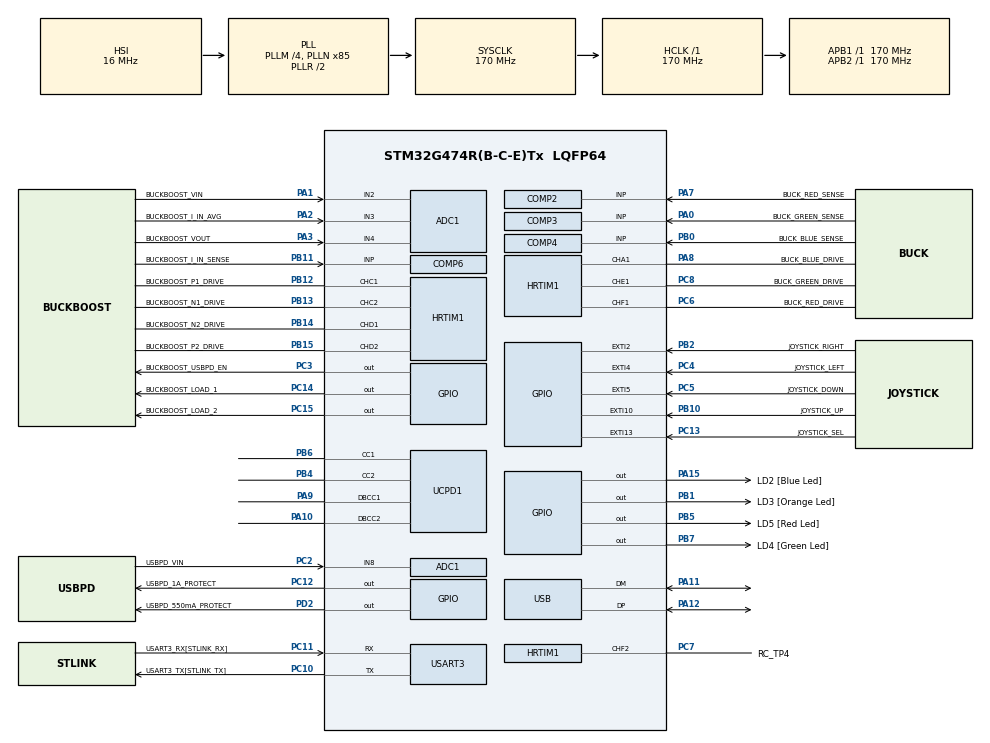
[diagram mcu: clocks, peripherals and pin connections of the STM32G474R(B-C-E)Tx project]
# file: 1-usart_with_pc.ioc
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ADC1.Channel-0\#ChannelRegularConversion=ADC_CHANNEL_8
ADC1.NbrOfConversionFlag=1
ADC1.OffsetNumber-0\#ChannelRegularConversion=ADC_OFFSET_NONE
ADC1.Rank-0\#ChannelRegularConversion=1
ADC1.SamplingTime-0\#ChannelRegularConversion=ADC_SAMPLETIME_2CYCLES_5
ADC1.master=1
DAC3.DAC_Channel-DAC_OUT2_Int=DAC_CHANNEL_2
Mcu.Family=STM32G4
Mcu.Name=STM32G474R(B-C-E)Tx
Mcu.Package=LQFP64
NVIC.ADC1_2_IRQn=true\:0\:0\:false\:false\:true\:true\:true
NVIC.EXTI15_10_IRQn=true\:0\:0\:false\:false\:true\:true\:true
NVIC.EXTI2_IRQn=true\:0\:0\:false\:false\:true\:true\:true
NVIC.EXTI4_IRQn=true\:0\:0\:false\:false\:true\:true\:true
NVIC.EXTI9_5_IRQn=true\:0\:0\:false\:false\:true\:true\:true
NVIC.HRTIM1_Master_IRQn=true\:0\:0\:false\:false\:true\:true\:true
NVIC.HRTIM1_TIMF_IRQn=true\:0\:0\:false\:false\:true\:true\:true
NVIC.PriorityGroup=NVIC_PRIORITYGROUP_4
NVIC.USART3_IRQn=true\:0\:0\:false\:false\:true\:true\:true
NVIC.USB_HP_IRQn=true\:0\:0\:false\:false\:true\:true\:true
PA0.GPIO_Label=BUCK_GREEN_SENSE
PA0.Mode=INP
PA0.Signal=COMP3_INP
PA1.GPIO_Label=BUCKBOOST_VIN
PA1.Mode=IN2-Single-Ended
PA1.Signal=ADC1_IN2
PA10.Mode=EnableDeadBattery
PA10.Signal=UCPD1_DBCC2
PA11.Mode=Device
PA11.Signal=USB_DM
PA12.Mode=Device
PA12.Signal=USB_DP
PA13.Mode=Serial_Wire
PA13.Signal=SYS_JTMS-SWDIO
PA14.Mode=Serial_Wire
PA14.Signal=SYS_JTCK-SWCLK
PA15.GPIO_Label=LD2 [Blue Led]
PA15.Signal=GPIO_Output
PA2.GPIO_Label=BUCKBOOST_I_IN_AVG
PA2.Mode=IN3-Single-Ended
PA2.Signal=ADC1_IN3
PA3.GPIO_Label=BUCKBOOST_VOUT
PA3.Mode=IN4-Single-Ended
PA3.Signal=ADC1_IN4
PA7.GPIO_Label=BUCK_RED_SENSE
PA7.Mode=INP
PA7.Signal=COMP2_INP
PA8.GPIO_Label=BUCK_BLUE_DRIVE
PA8.Mode=Output_TA1
PA8.Signal=HRTIM1_CHA1
PA9.Mode=EnableDeadBattery
PA9.Signal=UCPD1_DBCC1
PB0.GPIO_Label=BUCK_BLUE_SENSE
PB0.Mode=INP
PB0.Signal=COMP4_INP
PB1.GPIO_Label=LD3 [Orange Led]
PB1.Signal=GPIO_Output
PB10.GPIO_Label=JOYSTICK_UP
PB10.GPIO_PuPd=GPIO_PULLUP
PB10.Signal=GPXTI10
PB11.GPIO_Label=BUCKBOOST_I_IN_SENSE
PB11.Mode=INP
PB11.Signal=COMP6_INP
PB12.GPIO_Label=BUCKBOOST_P1_DRIVE
PB12.Mode=Output_TC1TC2
PB12.Signal=HRTIM1_CHC1
PB13.GPIO_Label=BUCKBOOST_N1_DRIVE
PB13.Mode=Output_TC1TC2
PB13.Signal=HRTIM1_CHC2
PB14.GPIO_Label=BUCKBOOST_N2_DRIVE
PB14.Mode=Output_TD1TD2
PB14.Signal=HRTIM1_CHD1
PB15.GPIO_Label=BUCKBOOST_P2_DRIVE
PB15.Mode=Output_TD1TD2
PB15.Signal=HRTIM1_CHD2
PB2.GPIO_Label=JOYSTICK_RIGHT
PB2.GPIO_PuPd=GPIO_PULLUP
PB2.Signal=GPXTI2
PB3.Signal=SYS_JTDO-SWO
PB4.Mode=Sink_AllSignals
PB4.Signal=UCPD1_CC2
PB5.GPIO_Label=LD5 [Red Led]
PB5.Signal=GPIO_Output
PB6.Mode=Sink_AllSignals
PB6.Signal=UCPD1_CC1
PB7.GPIO_Label=LD4 [Green Led]
PB7.Signal=GPIO_Output
PC10.GPIO_Label=USART3_TX[STLINK_TX]
PC10.GPIO_Speed=GPIO_SPEED_FREQ_MEDIUM
PC10.Mode=Asynchronous
PC10.Signal=USART3_TX
PC11.GPIO_Label=USART3_RX[STLINK_RX]
PC11.GPIO_Speed=GPIO_SPEED_FREQ_MEDIUM
PC11.Mode=Asynchronous
PC11.Signal=USART3_RX
PC12.GPIO_Label=USBPD_1A_PROTECT
PC12.Signal=GPIO_Output
PC13.GPIO_Label=JOYSTICK_SEL
PC13.GPIO_PuPd=GPIO_PULLUP
PC13.Signal=GPXTI13
PC14-OSC32_IN.GPIO_Label=BUCKBOOST_LOAD_1
PC14-OSC32_IN.Signal=GPIO_Output
PC15-OSC32_OUT.GPIO_Label=BUCKBOOST_LOAD_2
PC15-OSC32_OUT.Signal=GPIO_Output
PC2.GPIO_Label=USBPD_VIN
PC2.Mode=IN8-Single-Ended
PC2.Signal=ADC1_IN8
PC3.GPIO_Label=BUCKBOOST_USBPD_EN
PC3.Signal=GPIO_Output
PC4.GPIO_Label=JOYSTICK_LEFT
PC4.GPIO_PuPd=GPIO_PULLUP
PC4.Signal=GPXTI4
PC5.GPIO_Label=JOYSTICK_DOWN
PC5.GPIO_PuPd=GPIO_PULLUP
PC5.Signal=GPXTI5
PC6.GPIO_Label=BUCK_RED_DRIVE
PC6.Mode=Output_TF1TF2
PC6.Signal=HRTIM1_CHF1
PC7.GPIO_Label=RC_TP4
PC7.Mode=Output_TF1TF2
PC7.Signal=HRTIM1_CHF2
PC8.GPIO_Label=BUCK_GREEN_DRIVE
PC8.Mode=Output_TE1
PC8.Signal=HRTIM1_CHE1
PD2.GPIO_Label=USBPD_550mA_PROTECT
PD2.Signal=GPIO_Output
ProjectManager.HeapSize=0x200
ProjectManager.StackSize=0x400
ProjectManager.TargetToolchain=STM32CubeIDE
RCC.ADC12Freq_Value=170000000
RCC.ADC345Freq_Value=170000000
RCC.AHBFreq_Value=170000000
RCC.APB1Freq_Value=170000000
RCC.APB1TimFreq_Value=170000000
RCC.APB2Freq_Value=170000000
RCC.APB2TimFreq_Value=170000000
RCC.CK48CLockSelection=RCC_USBCLKSOURCE_HSI48
RCC.CortexFreq_Value=170000000
RCC.EXTERNAL_CLOCK_VALUE=12288000
RCC.HCLKFreq_Value=170000000
RCC.HSE_VALUE=8000000
RCC.HSI48_VALUE=48000000
RCC.HSI_VALUE=16000000
RCC.LSE_VALUE=32768
RCC.PLLM=RCC_PLLM_DIV4
RCC.PLLN=85
RCC.PLLP=RCC_PLLP_DIV8
RCC.PLLQ=RCC_PLLQ_DIV8
RCC.SYSCLKFreq_VALUE=170000000
RCC.SYSCLKSource=RCC_SYSCLKSOURCE_PLLCLK
RCC.USBFreq_Value=48000000
RCC.VCOOutputFreq_Value=340000000
USART3.ClockPrescaler=PRESCALER_DIV4
USART3.VirtualMode-Asynchronous=VM_ASYNC
USART3.WordLength=WORDLENGTH_8B
VP_COMP2_VS_DAC3OUT2.Mode=INM_DAC3OUT2
VP_COMP3_VS_DAC3OUT1.Mode=INM_DAC3OUT1
VP_COMP4_VS_DAC1OUT1.Mode=INM_DAC1OUT1
VP_COMP6_VS_DAC2OUT1.Mode=INM_DAC2OUT1
VP_DAC1_VS_DACI1.Mode=DAC_OUT1_Int
VP_DAC2_VS_DACI1.Mode=DAC_OUT1_Int
VP_DAC3_VS_DACI1.Mode=DAC_OUT1_Int
VP_DAC3_VS_DACI2.Mode=DAC_OUT2_Int
VP_SYS_VS_DBSignals.Mode=DisableDeadBatterySignals
board=B-G474E-DPOW1

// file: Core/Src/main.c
/* USER CODE BEGIN Header */
/**
  ******************************************************************************
  * @file           : main.c
  * @brief          : Main program body
  ******************************************************************************
  * @attention
  *
  * <h2><center>&copy; Copyright (c) 2020 STMicroelectronics.
  * All rights reserved.</center></h2>
  *
  * This software component is licensed by ST under BSD 3-Clause license,
  * the "License"; You may not use this file except in compliance with the
  * License. You may obtain a copy of the License at:
  *                        opensource.org/licenses/BSD-3-Clause
  *
  ******************************************************************************
  */
/* USER CODE END Header */

#include "main.h"

/* USER CODE BEGIN PD */
#define LF 0x0A
/* USER CODE END PD */

ADC_HandleTypeDef hadc1;

COMP_HandleTypeDef hcomp2;
COMP_HandleTypeDef hcomp3;
COMP_HandleTypeDef hcomp4;
COMP_HandleTypeDef hcomp6;

DAC_HandleTypeDef hdac1;
DAC_HandleTypeDef hdac2;
DAC_HandleTypeDef hdac3;

HRTIM_HandleTypeDef hhrtim1;

UART_HandleTypeDef huart3;

PCD_HandleTypeDef hpcd_USB_FS;

void SystemClock_Config(void);
static void MX_GPIO_Init(void);
static void MX_ADC1_Init(void);
static void MX_COMP2_Init(void);
static void MX_COMP3_Init(void);
static void MX_COMP4_Init(void);
static void MX_COMP6_Init(void);
static void MX_DAC1_Init(void);
static void MX_DAC2_Init(void);
static void MX_DAC3_Init(void);
static void MX_HRTIM1_Init(void);
static void MX_UCPD1_Init(void);
static void MX_USART3_UART_Init(void);
static void MX_USB_PCD_Init(void);

/* USER CODE BEGIN 0 */
char message[255] = "Comunicacao estabelecida...\n";

/* USER CODE END 0 */

int main(void)
{

  /* MCU Configuration--------------------------------------------------------*/

  /* Reset of all peripherals, Initializes the Flash interface and the Systick. */
  HAL_Init();

  /* Configure the system clock */
  SystemClock_Config();

  /* Initialize all configured peripherals */
  MX_GPIO_Init();
  MX_ADC1_Init();
  MX_COMP2_Init();
  MX_COMP3_Init();
  MX_COMP4_Init();
  MX_COMP6_Init();
  MX_DAC1_Init();
  MX_DAC2_Init();
  MX_DAC3_Init();
  MX_HRTIM1_Init();
  MX_UCPD1_Init();
  MX_USART3_UART_Init();
  MX_USB_PCD_Init();
  /* USER CODE BEGIN 2 */

  // Inicializa transmissão em modo de interrupção

  /* USER CODE END 2 */
  HAL_UART_TransmitIT(&huart3, (uint8_t*)message, 28);
  HAL_UART_Receive_IT(&huart3, (uint8_t*)message, 1);

  /* Infinite loop */
  while (1)
  {
	  int i = -1;
	  do{
		  i++;
		  HAL_UART_Receive(&huart3, (uint8_t*)(message+i), 1, HAL_MAX_DELAY);
	  }
	  while(message[i] != LF);

	  HAL_UART_Transmit(&huart3, (uint8_t*)message, ++i, HAL_MAX_DELAY);

  }
}

void SystemClock_Config(void)
{
  RCC_OscInitTypeDef RCC_OscInitStruct = {0};
  RCC_ClkInitTypeDef RCC_ClkInitStruct = {0};
  RCC_PeriphCLKInitTypeDef PeriphClkInit = {0};

  /** Configure the main internal regulator output voltage
  */
  HAL_PWREx_ControlVoltageScaling(PWR_REGULATOR_VOLTAGE_SCALE1_BOOST);
  /** Initializes the CPU, AHB and APB busses clocks
  */
  RCC_OscInitStruct.OscillatorType = RCC_OSCILLATORTYPE_HSI|RCC_OSCILLATORTYPE_HSI48;
  RCC_OscInitStruct.HSIState = RCC_HSI_ON;
  RCC_OscInitStruct.HSICalibrationValue = RCC_HSICALIBRATION_DEFAULT;
  RCC_OscInitStruct.HSI48State = RCC_HSI48_ON;
  RCC_OscInitStruct.PLL.PLLState = RCC_PLL_ON;
  RCC_OscInitStruct.PLL.PLLSource = RCC_PLLSOURCE_HSI;
  RCC_OscInitStruct.PLL.PLLM = RCC_PLLM_DIV4;
  RCC_OscInitStruct.PLL.PLLN = 85;
  RCC_OscInitStruct.PLL.PLLP = RCC_PLLP_DIV8;
  RCC_OscInitStruct.PLL.PLLQ = RCC_PLLQ_DIV8;
  RCC_OscInitStruct.PLL.PLLR = RCC_PLLR_DIV2;
  if (HAL_RCC_OscConfig(&RCC_OscInitStruct) != HAL_OK)
  {
    Error_Handler();
  }
  /** Initializes the CPU, AHB and APB busses clocks
  */
  RCC_ClkInitStruct.ClockType = RCC_CLOCKTYPE_HCLK|RCC_CLOCKTYPE_SYSCLK
                              |RCC_CLOCKTYPE_PCLK1|RCC_CLOCKTYPE_PCLK2;
  RCC_ClkInitStruct.SYSCLKSource = RCC_SYSCLKSOURCE_PLLCLK;
  RCC_ClkInitStruct.AHBCLKDivider = RCC_SYSCLK_DIV1;
  RCC_ClkInitStruct.APB1CLKDivider = RCC_HCLK_DIV1;
  RCC_ClkInitStruct.APB2CLKDivider = RCC_HCLK_DIV1;

  if (HAL_RCC_ClockConfig(&RCC_ClkInitStruct, FLASH_LATENCY_8) != HAL_OK)
  {
    Error_Handler();
  }
  /** Initializes the peripherals clocks
  */
  PeriphClkInit.PeriphClockSelection = RCC_PERIPHCLK_USART3|RCC_PERIPHCLK_USB
                              |RCC_PERIPHCLK_ADC12;
  PeriphClkInit.Usart3ClockSelection = RCC_USART3CLKSOURCE_PCLK1;
  PeriphClkInit.UsbClockSelection = RCC_USBCLKSOURCE_HSI48;
  PeriphClkInit.Adc12ClockSelection = RCC_ADC12CLKSOURCE_SYSCLK;
  if (HAL_RCCEx_PeriphCLKConfig(&PeriphClkInit) != HAL_OK)
  {
    Error_Handler();
  }
}

static void MX_ADC1_Init(void)
{

  ADC_MultiModeTypeDef multimode = {0};
  ADC_ChannelConfTypeDef sConfig = {0};

  /** Common config
  */
  hadc1.Instance = ADC1;
  hadc1.Init.ClockPrescaler = ADC_CLOCK_ASYNC_DIV1;
  hadc1.Init.Resolution = ADC_RESOLUTION_12B;
  hadc1.Init.DataAlign = ADC_DATAALIGN_RIGHT;
  hadc1.Init.GainCompensation = 0;
  hadc1.Init.ScanConvMode = ADC_SCAN_DISABLE;
  hadc1.Init.EOCSelection = ADC_EOC_SINGLE_CONV;
  hadc1.Init.LowPowerAutoWait = DISABLE;
  hadc1.Init.ContinuousConvMode = DISABLE;
  hadc1.Init.NbrOfConversion = 1;
  hadc1.Init.DiscontinuousConvMode = DISABLE;
  hadc1.Init.ExternalTrigConv = ADC_SOFTWARE_START;
  hadc1.Init.ExternalTrigConvEdge = ADC_EXTERNALTRIGCONVEDGE_NONE;
  hadc1.Init.DMAContinuousRequests = DISABLE;
  hadc1.Init.Overrun = ADC_OVR_DATA_PRESERVED;
  hadc1.Init.OversamplingMode = DISABLE;
  if (HAL_ADC_Init(&hadc1) != HAL_OK)
  {
    Error_Handler();
  }
  /** Configure the ADC multi-mode
  */
  multimode.Mode = ADC_MODE_INDEPENDENT;
  if (HAL_ADCEx_MultiModeConfigChannel(&hadc1, &multimode) != HAL_OK)
  {
    Error_Handler();
  }
  /** Configure Regular Channel
  */
  sConfig.Channel = ADC_CHANNEL_8;
  sConfig.Rank = ADC_REGULAR_RANK_1;
  sConfig.SamplingTime = ADC_SAMPLETIME_2CYCLES_5;
  sConfig.SingleDiff = ADC_SINGLE_ENDED;
  sConfig.OffsetNumber = ADC_OFFSET_NONE;
  sConfig.Offset = 0;
  if (HAL_ADC_ConfigChannel(&hadc1, &sConfig) != HAL_OK)
  {
    Error_Handler();
  }

}

static void MX_COMP2_Init(void)
{

  hcomp2.Instance = COMP2;
  hcomp2.Init.InputPlus = COMP_INPUT_PLUS_IO1;
  hcomp2.Init.InputMinus = COMP_INPUT_MINUS_DAC3_CH2;
  hcomp2.Init.OutputPol = COMP_OUTPUTPOL_NONINVERTED;
  hcomp2.Init.Hysteresis = COMP_HYSTERESIS_NONE;
  hcomp2.Init.BlankingSrce = COMP_BLANKINGSRC_NONE;
  hcomp2.Init.TriggerMode = COMP_TRIGGERMODE_NONE;
  if (HAL_COMP_Init(&hcomp2) != HAL_OK)
  {
    Error_Handler();
  }

}

static void MX_COMP3_Init(void)
{

  hcomp3.Instance = COMP3;
  hcomp3.Init.InputPlus = COMP_INPUT_PLUS_IO1;
  hcomp3.Init.InputMinus = COMP_INPUT_MINUS_DAC3_CH1;
  hcomp3.Init.OutputPol = COMP_OUTPUTPOL_NONINVERTED;
  hcomp3.Init.Hysteresis = COMP_HYSTERESIS_NONE;
  hcomp3.Init.BlankingSrce = COMP_BLANKINGSRC_NONE;
  hcomp3.Init.TriggerMode = COMP_TRIGGERMODE_NONE;
  if (HAL_COMP_Init(&hcomp3) != HAL_OK)
  {
    Error_Handler();
  }

}

static void MX_COMP4_Init(void)
{

  hcomp4.Instance = COMP4;
  hcomp4.Init.InputPlus = COMP_INPUT_PLUS_IO1;
  hcomp4.Init.InputMinus = COMP_INPUT_MINUS_DAC1_CH1;
  hcomp4.Init.OutputPol = COMP_OUTPUTPOL_NONINVERTED;
  hcomp4.Init.Hysteresis = COMP_HYSTERESIS_NONE;
  hcomp4.Init.BlankingSrce = COMP_BLANKINGSRC_NONE;
  hcomp4.Init.TriggerMode = COMP_TRIGGERMODE_NONE;
  if (HAL_COMP_Init(&hcomp4) != HAL_OK)
  {
    Error_Handler();
  }

}

static void MX_COMP6_Init(void)
{

  hcomp6.Instance = COMP6;
  hcomp6.Init.InputPlus = COMP_INPUT_PLUS_IO1;
  hcomp6.Init.InputMinus = COMP_INPUT_MINUS_DAC2_CH1;
  hcomp6.Init.OutputPol = COMP_OUTPUTPOL_NONINVERTED;
  hcomp6.Init.Hysteresis = COMP_HYSTERESIS_NONE;
  hcomp6.Init.BlankingSrce = COMP_BLANKINGSRC_NONE;
  hcomp6.Init.TriggerMode = COMP_TRIGGERMODE_NONE;
  if (HAL_COMP_Init(&hcomp6) != HAL_OK)
  {
    Error_Handler();
  }

}

static void MX_DAC1_Init(void)
{

  DAC_ChannelConfTypeDef sConfig = {0};

  /** DAC Initialization
  */
  hdac1.Instance = DAC1;
  if (HAL_DAC_Init(&hdac1) != HAL_OK)
  {
    Error_Handler();
  }
  /** DAC channel OUT1 config
  */
  sConfig.DAC_HighFrequency = DAC_HIGH_FREQUENCY_INTERFACE_MODE_AUTOMATIC;
  sConfig.DAC_DMADoubleDataMode = DISABLE;
  sConfig.DAC_SignedFormat = DISABLE;
  sConfig.DAC_SampleAndHold = DAC_SAMPLEANDHOLD_DISABLE;
  sConfig.DAC_Trigger = DAC_TRIGGER_NONE;
  sConfig.DAC_Trigger2 = DAC_TRIGGER_NONE;
  sConfig.DAC_OutputBuffer = DAC_OUTPUTBUFFER_DISABLE;
  sConfig.DAC_ConnectOnChipPeripheral = DAC_CHIPCONNECT_ENABLE;
  sConfig.DAC_UserTrimming = DAC_TRIMMING_FACTORY;
  if (HAL_DAC_ConfigChannel(&hdac1, &sConfig, DAC_CHANNEL_1) != HAL_OK)
  {
    Error_Handler();
  }

}

static void MX_DAC2_Init(void)
{

  DAC_ChannelConfTypeDef sConfig = {0};

  /** DAC Initialization
  */
  hdac2.Instance = DAC2;
  if (HAL_DAC_Init(&hdac2) != HAL_OK)
  {
    Error_Handler();
  }
  /** DAC channel OUT1 config
  */
  sConfig.DAC_HighFrequency = DAC_HIGH_FREQUENCY_INTERFACE_MODE_AUTOMATIC;
  sConfig.DAC_DMADoubleDataMode = DISABLE;
  sConfig.DAC_SignedFormat = DISABLE;
  sConfig.DAC_SampleAndHold = DAC_SAMPLEANDHOLD_DISABLE;
  sConfig.DAC_Trigger = DAC_TRIGGER_NONE;
  sConfig.DAC_Trigger2 = DAC_TRIGGER_NONE;
  sConfig.DAC_OutputBuffer = DAC_OUTPUTBUFFER_DISABLE;
  sConfig.DAC_ConnectOnChipPeripheral = DAC_CHIPCONNECT_ENABLE;
  sConfig.DAC_UserTrimming = DAC_TRIMMING_FACTORY;
  if (HAL_DAC_ConfigChannel(&hdac2, &sConfig, DAC_CHANNEL_1) != HAL_OK)
  {
    Error_Handler();
  }

}

static void MX_DAC3_Init(void)
{

  DAC_ChannelConfTypeDef sConfig = {0};

  /** DAC Initialization
  */
  hdac3.Instance = DAC3;
  if (HAL_DAC_Init(&hdac3) != HAL_OK)
  {
    Error_Handler();
  }
  /** DAC channel OUT1 config
  */
  sConfig.DAC_HighFrequency = DAC_HIGH_FREQUENCY_INTERFACE_MODE_AUTOMATIC;
  sConfig.DAC_DMADoubleDataMode = DISABLE;
  sConfig.DAC_SignedFormat = DISABLE;
  sConfig.DAC_SampleAndHold = DAC_SAMPLEANDHOLD_DISABLE;
  sConfig.DAC_Trigger = DAC_TRIGGER_NONE;
  sConfig.DAC_Trigger2 = DAC_TRIGGER_NONE;
  sConfig.DAC_OutputBuffer = DAC_OUTPUTBUFFER_DISABLE;
  sConfig.DAC_ConnectOnChipPeripheral = DAC_CHIPCONNECT_ENABLE;
  sConfig.DAC_UserTrimming = DAC_TRIMMING_FACTORY;
  if (HAL_DAC_ConfigChannel(&hdac3, &sConfig, DAC_CHANNEL_1) != HAL_OK)
  {
    Error_Handler();
  }
  /** DAC channel OUT2 config
  */
  sConfig.DAC_ConnectOnChipPeripheral = DAC_CHIPCONNECT_ENABLE;
  if (HAL_DAC_ConfigChannel(&hdac3, &sConfig, DAC_CHANNEL_2) != HAL_OK)
  {
    Error_Handler();
  }

}

static void MX_HRTIM1_Init(void)
{

  HRTIM_TimeBaseCfgTypeDef pTimeBaseCfg = {0};
  HRTIM_TimerCtlTypeDef pTimerCtl = {0};
  HRTIM_TimerCfgTypeDef pTimerCfg = {0};
  HRTIM_OutputCfgTypeDef pOutputCfg = {0};

  hhrtim1.Instance = HRTIM1;
  hhrtim1.Init.HRTIMInterruptResquests = HRTIM_IT_NONE;
  hhrtim1.Init.SyncOptions = HRTIM_SYNCOPTION_NONE;
  if (HAL_HRTIM_Init(&hhrtim1) != HAL_OK)
  {
    Error_Handler();
  }
  if (HAL_HRTIM_DLLCalibrationStart(&hhrtim1, HRTIM_CALIBRATIONRATE_3) != HAL_OK)
  {
    Error_Handler();
  }
  if (HAL_HRTIM_PollForDLLCalibration(&hhrtim1, 10) != HAL_OK)
  {
    Error_Handler();
  }
  pTimeBaseCfg.Period = 0xFFDF;
  pTimeBaseCfg.RepetitionCounter = 0x00;
  pTimeBaseCfg.PrescalerRatio = HRTIM_PRESCALERRATIO_MUL32;
  pTimeBaseCfg.Mode = HRTIM_MODE_CONTINUOUS;
  if (HAL_HRTIM_TimeBaseConfig(&hhrtim1, HRTIM_TIMERINDEX_TIMER_A, &pTimeBaseCfg) != HAL_OK)
  {
    Error_Handler();
  }
  pTimerCtl.UpDownMode = HRTIM_TIMERUPDOWNMODE_UP;
  pTimerCtl.DualChannelDacEnable = HRTIM_TIMER_DCDE_DISABLED;
  if (HAL_HRTIM_WaveformTimerControl(&hhrtim1, HRTIM_TIMERINDEX_TIMER_A, &pTimerCtl) != HAL_OK)
  {
    Error_Handler();
  }
  pTimerCfg.InterruptRequests = HRTIM_TIM_IT_NONE;
  pTimerCfg.DMARequests = HRTIM_TIM_DMA_NONE;
  pTimerCfg.DMASrcAddress = 0x0000;
  pTimerCfg.DMADstAddress = 0x0000;
  pTimerCfg.DMASize = 0x1;
  pTimerCfg.HalfModeEnable = HRTIM_HALFMODE_DISABLED;
  pTimerCfg.InterleavedMode = HRTIM_INTERLEAVED_MODE_DISABLED;
  pTimerCfg.StartOnSync = HRTIM_SYNCSTART_DISABLED;
  pTimerCfg.ResetOnSync = HRTIM_SYNCRESET_DISABLED;
  pTimerCfg.DACSynchro = HRTIM_DACSYNC_NONE;
  pTimerCfg.PreloadEnable = HRTIM_PRELOAD_DISABLED;
  pTimerCfg.UpdateGating = HRTIM_UPDATEGATING_INDEPENDENT;
  pTimerCfg.BurstMode = HRTIM_TIMERBURSTMODE_MAINTAINCLOCK;
  pTimerCfg.RepetitionUpdate = HRTIM_UPDATEONREPETITION_DISABLED;
  pTimerCfg.PushPull = HRTIM_TIMPUSHPULLMODE_DISABLED;
  pTimerCfg.FaultEnable = HRTIM_TIMFAULTENABLE_NONE;
  pTimerCfg.FaultLock = HRTIM_TIMFAULTLOCK_READWRITE;
  pTimerCfg.DeadTimeInsertion = HRTIM_TIMDEADTIMEINSERTION_DISABLED;
  pTimerCfg.DelayedProtectionMode = HRTIM_TIMER_A_B_C_DELAYEDPROTECTION_DISABLED;
  pTimerCfg.UpdateTrigger = HRTIM_TIMUPDATETRIGGER_NONE;
  pTimerCfg.ResetTrigger = HRTIM_TIMRESETTRIGGER_NONE;
  pTimerCfg.ResetUpdate = HRTIM_TIMUPDATEONRESET_DISABLED;
  pTimerCfg.ReSyncUpdate = HRTIM_TIMERESYNC_UPDATE_UNCONDITIONAL;
  if (HAL_HRTIM_WaveformTimerConfig(&hhrtim1, HRTIM_TIMERINDEX_TIMER_A, &pTimerCfg) != HAL_OK)
  {
    Error_Handler();
  }
  pTimerCfg.DMASrcAddress = 0x0000;
  pTimerCfg.DMADstAddress = 0x0000;
  pTimerCfg.DMASize = 0x1;
  if (HAL_HRTIM_WaveformTimerConfig(&hhrtim1, HRTIM_TIMERINDEX_TIMER_C, &pTimerCfg) != HAL_OK)
  {
    Error_Handler();
  }
  pTimerCfg.DMASrcAddress = 0x0000;
  pTimerCfg.DMADstAddress = 0x0000;
  pTimerCfg.DMASize = 0x1;
  pTimerCfg.DelayedProtectionMode = HRTIM_TIMER_D_E_DELAYEDPROTECTION_DISABLED;
  if (HAL_HRTIM_WaveformTimerConfig(&hhrtim1, HRTIM_TIMERINDEX_TIMER_D, &pTimerCfg) != HAL_OK)
  {
    Error_Handler();
  }
  pTimerCfg.InterruptRequests = HRTIM_MASTER_IT_NONE;
  pTimerCfg.DMASrcAddress = 0x0000;
  pTimerCfg.DMADstAddress = 0x0000;
  pTimerCfg.DMASize = 0x1;
  if (HAL_HRTIM_WaveformTimerConfig(&hhrtim1, HRTIM_TIMERINDEX_TIMER_E, &pTimerCfg) != HAL_OK)
  {
    Error_Handler();
  }
  pTimerCfg.InterruptRequests = HRTIM_TIM_IT_NONE;
  pTimerCfg.DMASrcAddress = 0x0000;
  pTimerCfg.DMADstAddress = 0x0000;
  pTimerCfg.DMASize = 0x1;
  pTimerCfg.DelayedProtectionMode = HRTIM_TIMER_F_DELAYEDPROTECTION_DISABLED;
  if (HAL_HRTIM_WaveformTimerConfig(&hhrtim1, HRTIM_TIMERINDEX_TIMER_F, &pTimerCfg) != HAL_OK)
  {
    Error_Handler();
  }
  pOutputCfg.Polarity = HRTIM_OUTPUTPOLARITY_HIGH;
  pOutputCfg.SetSource = HRTIM_OUTPUTSET_NONE;
  pOutputCfg.ResetSource = HRTIM_OUTPUTRESET_NONE;
  pOutputCfg.IdleMode = HRTIM_OUTPUTIDLEMODE_NONE;
  pOutputCfg.IdleLevel = HRTIM_OUTPUTIDLELEVEL_INACTIVE;
  pOutputCfg.FaultLevel = HRTIM_OUTPUTFAULTLEVEL_NONE;
  pOutputCfg.ChopperModeEnable = HRTIM_OUTPUTCHOPPERMODE_DISABLED;
  pOutputCfg.BurstModeEntryDelayed = HRTIM_OUTPUTBURSTMODEENTRY_REGULAR;
  if (HAL_HRTIM_WaveformOutputConfig(&hhrtim1, HRTIM_TIMERINDEX_TIMER_A, HRTIM_OUTPUT_TA1, &pOutputCfg) != HAL_OK)
  {
    Error_Handler();
  }
  if (HAL_HRTIM_WaveformOutputConfig(&hhrtim1, HRTIM_TIMERINDEX_TIMER_C, HRTIM_OUTPUT_TC1, &pOutputCfg) != HAL_OK)
  {
    Error_Handler();
  }
  if (HAL_HRTIM_WaveformOutputConfig(&hhrtim1, HRTIM_TIMERINDEX_TIMER_D, HRTIM_OUTPUT_TD1, &pOutputCfg) != HAL_OK)
  {
    Error_Handler();
  }
  if (HAL_HRTIM_WaveformOutputConfig(&hhrtim1, HRTIM_TIMERINDEX_TIMER_E, HRTIM_OUTPUT_TE1, &pOutputCfg) != HAL_OK)
  {
    Error_Handler();
  }
  if (HAL_HRTIM_WaveformOutputConfig(&hhrtim1, HRTIM_TIMERINDEX_TIMER_F, HRTIM_OUTPUT_TF1, &pOutputCfg) != HAL_OK)
  {
    Error_Handler();
  }
  if (HAL_HRTIM_TimeBaseConfig(&hhrtim1, HRTIM_TIMERINDEX_TIMER_C, &pTimeBaseCfg) != HAL_OK)
  {
    Error_Handler();
  }
  if (HAL_HRTIM_WaveformTimerControl(&hhrtim1, HRTIM_TIMERINDEX_TIMER_C, &pTimerCtl) != HAL_OK)
  {
    Error_Handler();
  }
  if (HAL_HRTIM_WaveformOutputConfig(&hhrtim1, HRTIM_TIMERINDEX_TIMER_C, HRTIM_OUTPUT_TC2, &pOutputCfg) != HAL_OK)
  {
    Error_Handler();
  }
  if (HAL_HRTIM_WaveformOutputConfig(&hhrtim1, HRTIM_TIMERINDEX_TIMER_D, HRTIM_OUTPUT_TD2, &pOutputCfg) != HAL_OK)
  {
    Error_Handler();
  }
  if (HAL_HRTIM_WaveformOutputConfig(&hhrtim1, HRTIM_TIMERINDEX_TIMER_F, HRTIM_OUTPUT_TF2, &pOutputCfg) != HAL_OK)
  {
    Error_Handler();
  }
  if (HAL_HRTIM_TimeBaseConfig(&hhrtim1, HRTIM_TIMERINDEX_TIMER_D, &pTimeBaseCfg) != HAL_OK)
  {
    Error_Handler();
  }
  if (HAL_HRTIM_WaveformTimerControl(&hhrtim1, HRTIM_TIMERINDEX_TIMER_D, &pTimerCtl) != HAL_OK)
  {
    Error_Handler();
  }
  if (HAL_HRTIM_TimeBaseConfig(&hhrtim1, HRTIM_TIMERINDEX_TIMER_E, &pTimeBaseCfg) != HAL_OK)
  {
    Error_Handler();
  }
  if (HAL_HRTIM_WaveformTimerControl(&hhrtim1, HRTIM_TIMERINDEX_TIMER_E, &pTimerCtl) != HAL_OK)
  {
    Error_Handler();
  }
  if (HAL_HRTIM_TimeBaseConfig(&hhrtim1, HRTIM_TIMERINDEX_TIMER_F, &pTimeBaseCfg) != HAL_OK)
  {
    Error_Handler();
  }
  if (HAL_HRTIM_WaveformTimerControl(&hhrtim1, HRTIM_TIMERINDEX_TIMER_F, &pTimerCtl) != HAL_OK)
  {
    Error_Handler();
  }
  HAL_HRTIM_MspPostInit(&hhrtim1);

}

static void MX_UCPD1_Init(void)
{

}

static void MX_USART3_UART_Init(void)
{

  huart3.Instance = USART3;
  huart3.Init.BaudRate = 115200;
  huart3.Init.WordLength = UART_WORDLENGTH_8B;
  huart3.Init.StopBits = UART_STOPBITS_1;
  huart3.Init.Parity = UART_PARITY_NONE;
  huart3.Init.Mode = UART_MODE_TX_RX;
  huart3.Init.HwFlowCtl = UART_HWCONTROL_NONE;
  huart3.Init.OverSampling = UART_OVERSAMPLING_16;
  huart3.Init.OneBitSampling = UART_ONE_BIT_SAMPLE_DISABLE;
  huart3.Init.ClockPrescaler = UART_PRESCALER_DIV4;
  huart3.AdvancedInit.AdvFeatureInit = UART_ADVFEATURE_NO_INIT;
  if (HAL_UART_Init(&huart3) != HAL_OK)
  {
    Error_Handler();
  }
  if (HAL_UARTEx_SetTxFifoThreshold(&huart3, UART_TXFIFO_THRESHOLD_1_8) != HAL_OK)
  {
    Error_Handler();
  }
  if (HAL_UARTEx_SetRxFifoThreshold(&huart3, UART_RXFIFO_THRESHOLD_1_8) != HAL_OK)
  {
    Error_Handler();
  }
  if (HAL_UARTEx_DisableFifoMode(&huart3) != HAL_OK)
  {
    Error_Handler();
  }

}

static void MX_USB_PCD_Init(void)
{

  hpcd_USB_FS.Instance = USB;
  hpcd_USB_FS.Init.dev_endpoints = 8;
  hpcd_USB_FS.Init.speed = PCD_SPEED_FULL;
  hpcd_USB_FS.Init.phy_itface = PCD_PHY_EMBEDDED;
  hpcd_USB_FS.Init.Sof_enable = DISABLE;
  hpcd_USB_FS.Init.low_power_enable = DISABLE;
  hpcd_USB_FS.Init.lpm_enable = DISABLE;
  hpcd_USB_FS.Init.battery_charging_enable = DISABLE;
  if (HAL_PCD_Init(&hpcd_USB_FS) != HAL_OK)
  {
    Error_Handler();
  }

}

static void MX_GPIO_Init(void)
{
  GPIO_InitTypeDef GPIO_InitStruct = {0};

  /* GPIO Ports Clock Enable */
  __HAL_RCC_GPIOC_CLK_ENABLE();
  __HAL_RCC_GPIOA_CLK_ENABLE();
  __HAL_RCC_GPIOB_CLK_ENABLE();
  __HAL_RCC_GPIOD_CLK_ENABLE();

  /*Configure GPIO pin Output Level */
  HAL_GPIO_WritePin(GPIOC, BUCKBOOST_LOAD_1_Pin|BUCKBOOST_LOAD_2_Pin|BUCKBOOST_USBPD_EN_Pin|USBPD_1A_PROTECT_Pin, GPIO_PIN_RESET);

  /*Configure GPIO pin Output Level */
  HAL_GPIO_WritePin(GPIOB, LD3_Pin|LD5_Pin|LD4_Pin, GPIO_PIN_RESET);

  /*Configure GPIO pin Output Level */
  HAL_GPIO_WritePin(LD2_GPIO_Port, LD2_Pin, GPIO_PIN_RESET);

  /*Configure GPIO pin Output Level */
  HAL_GPIO_WritePin(USBPD_550mA_PROTECT_GPIO_Port, USBPD_550mA_PROTECT_Pin, GPIO_PIN_RESET);

  /*Configure GPIO pins : JOYSTICK_SEL_Pin JOYSTICK_LEFT_Pin JOYSTICK_DOWN_Pin */
  GPIO_InitStruct.Pin = JOYSTICK_SEL_Pin|JOYSTICK_LEFT_Pin|JOYSTICK_DOWN_Pin;
  GPIO_InitStruct.Mode = GPIO_MODE_IT_RISING;
  GPIO_InitStruct.Pull = GPIO_PULLUP;
  HAL_GPIO_Init(GPIOC, &GPIO_InitStruct);

  /*Configure GPIO pins : BUCKBOOST_LOAD_1_Pin BUCKBOOST_LOAD_2_Pin BUCKBOOST_USBPD_EN_Pin USBPD_1A_PROTECT_Pin */
  GPIO_InitStruct.Pin = BUCKBOOST_LOAD_1_Pin|BUCKBOOST_LOAD_2_Pin|BUCKBOOST_USBPD_EN_Pin|USBPD_1A_PROTECT_Pin;
  GPIO_InitStruct.Mode = GPIO_MODE_OUTPUT_PP;
  GPIO_InitStruct.Pull = GPIO_NOPULL;
  GPIO_InitStruct.Speed = GPIO_SPEED_FREQ_LOW;
  HAL_GPIO_Init(GPIOC, &GPIO_InitStruct);

  /*Configure GPIO pins : LD3_Pin LD5_Pin LD4_Pin */
  GPIO_InitStruct.Pin = LD3_Pin|LD5_Pin|LD4_Pin;
  GPIO_InitStruct.Mode = GPIO_MODE_OUTPUT_PP;
  GPIO_InitStruct.Pull = GPIO_NOPULL;
  GPIO_InitStruct.Speed = GPIO_SPEED_FREQ_LOW;
  HAL_GPIO_Init(GPIOB, &GPIO_InitStruct);

  /*Configure GPIO pins : JOYSTICK_RIGHT_Pin JOYSTICK_UP_Pin */
  GPIO_InitStruct.Pin = JOYSTICK_RIGHT_Pin|JOYSTICK_UP_Pin;
  GPIO_InitStruct.Mode = GPIO_MODE_IT_RISING;
  GPIO_InitStruct.Pull = GPIO_PULLUP;
  HAL_GPIO_Init(GPIOB, &GPIO_InitStruct);

  /*Configure GPIO pin : LD2_Pin */
  GPIO_InitStruct.Pin = LD2_Pin;
  GPIO_InitStruct.Mode = GPIO_MODE_OUTPUT_PP;
  GPIO_InitStruct.Pull = GPIO_NOPULL;
  GPIO_InitStruct.Speed = GPIO_SPEED_FREQ_LOW;
  HAL_GPIO_Init(LD2_GPIO_Port, &GPIO_InitStruct);

  /*Configure GPIO pin : USBPD_550mA_PROTECT_Pin */
  GPIO_InitStruct.Pin = USBPD_550mA_PROTECT_Pin;
  GPIO_InitStruct.Mode = GPIO_MODE_OUTPUT_PP;
  GPIO_InitStruct.Pull = GPIO_NOPULL;
  GPIO_InitStruct.Speed = GPIO_SPEED_FREQ_LOW;
  HAL_GPIO_Init(USBPD_550mA_PROTECT_GPIO_Port, &GPIO_InitStruct);

  /* EXTI interrupt init*/
  HAL_NVIC_SetPriority(EXTI2_IRQn, 0, 0);
  HAL_NVIC_EnableIRQ(EXTI2_IRQn);

  HAL_NVIC_SetPriority(EXTI4_IRQn, 0, 0);
  HAL_NVIC_EnableIRQ(EXTI4_IRQn);

  HAL_NVIC_SetPriority(EXTI9_5_IRQn, 0, 0);
  HAL_NVIC_EnableIRQ(EXTI9_5_IRQn);

  HAL_NVIC_SetPriority(EXTI15_10_IRQn, 0, 0);
  HAL_NVIC_EnableIRQ(EXTI15_10_IRQn);

}

void Error_Handler(void)
{
}

/************************ (C) COPYRIGHT STMicroelectronics *****END OF FILE****/
